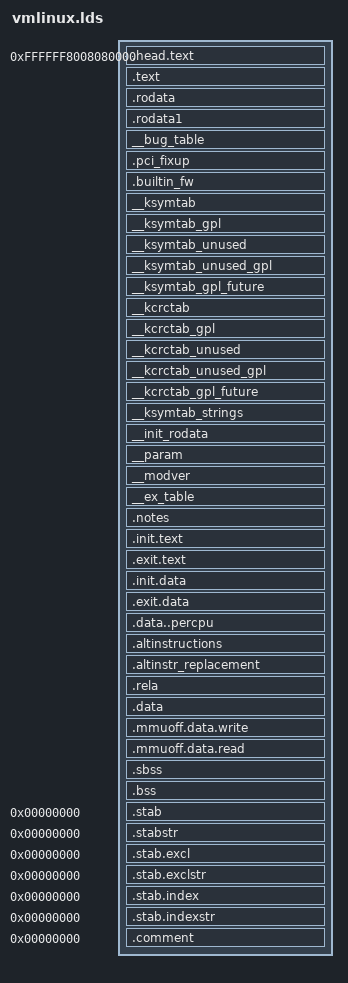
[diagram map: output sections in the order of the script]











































OUTPUT_ARCH(aarch64)
ENTRY(_text)

jiffies = jiffies_64;
PECOFF_FILE_ALIGNMENT = 0x200;
SECTIONS
{






 /DISCARD/ : {


  *(.exitcall.exit)
  *(.discard)
  *(.discard.*)
  *(.interp .dynamic)
  *(.dynsym .dynstr .hash)
 }

 . = ((((0xffffffffffffffff - (1 << (39)) + 1) + (0)) + (0x08000000))) + 0x00080000;

 .head.text : {
  _text = .;
  *(.head.text)
 }
 .text : {
  _stext = .;
   __exception_text_start = .;
   *(.exception.text)
   __exception_text_end = .;
   . = ALIGN(8); __irqentry_text_start = .; *(.irqentry.text) __irqentry_text_end = .;
   . = ALIGN(8); __entry_text_start = .; *(.entry.text) __entry_text_end = .;
   . = ALIGN(8); __softirqentry_text_start = .; *(.softirqentry.text) __softirqentry_text_end = .;
   . = ALIGN(8); *(.text.hot .text .text.fixup .text.unlikely) *(.ref.text)
   . = ALIGN(8); __sched_text_start = .; *(.sched.text) __sched_text_end = .;
   . = ALIGN(8); __cpuidle_text_start = .; *(.cpuidle.text) __cpuidle_text_end = .;
   . = ALIGN(8); __lock_text_start = .; *(.spinlock.text) __lock_text_end = .;
   . = ALIGN(8); __kprobes_text_start = .; *(.kprobes.text) __kprobes_text_end = .;
   . = ALIGN(0x00001000); __hyp_idmap_text_start = .; *(.hyp.idmap.text) __hyp_idmap_text_end = .; __hyp_text_start = .; *(.hyp.text) __hyp_text_end = .;
   . = ALIGN(0x00001000); __idmap_text_start = .; *(.idmap.text) __idmap_text_end = .;


   *(.fixup)
   *(.gnu.warning)
  . = ALIGN(16);
  *(.got)
 }

 . = ALIGN(0x00200000);
 _etext = .;

 . = ALIGN(((1 << 12))); .rodata : AT(ADDR(.rodata) - 0) { __start_rodata = .; *(.rodata) *(.rodata.*) *(.data..ro_after_init) *(__vermagic) . = ALIGN(8); __start___tracepoints_ptrs = .; *(__tracepoints_ptrs) __stop___tracepoints_ptrs = .; *(__tracepoints_strings) } .rodata1 : AT(ADDR(.rodata1) - 0) { *(.rodata1) } . = ALIGN(8); __bug_table : AT(ADDR(__bug_table) - 0) { __start___bug_table = .; *(__bug_table) __stop___bug_table = .; } .pci_fixup : AT(ADDR(.pci_fixup) - 0) { __start_pci_fixups_early = .; *(.pci_fixup_early) __end_pci_fixups_early = .; __start_pci_fixups_header = .; *(.pci_fixup_header) __end_pci_fixups_header = .; __start_pci_fixups_final = .; *(.pci_fixup_final) __end_pci_fixups_final = .; __start_pci_fixups_enable = .; *(.pci_fixup_enable) __end_pci_fixups_enable = .; __start_pci_fixups_resume = .; *(.pci_fixup_resume) __end_pci_fixups_resume = .; __start_pci_fixups_resume_early = .; *(.pci_fixup_resume_early) __end_pci_fixups_resume_early = .; __start_pci_fixups_suspend = .; *(.pci_fixup_suspend) __end_pci_fixups_suspend = .; __start_pci_fixups_suspend_late = .; *(.pci_fixup_suspend_late) __end_pci_fixups_suspend_late = .; } .builtin_fw : AT(ADDR(.builtin_fw) - 0) { __start_builtin_fw = .; *(.builtin_fw) __end_builtin_fw = .; } __ksymtab : AT(ADDR(__ksymtab) - 0) { __start___ksymtab = .; *(SORT(___ksymtab+*)) __stop___ksymtab = .; } __ksymtab_gpl : AT(ADDR(__ksymtab_gpl) - 0) { __start___ksymtab_gpl = .; *(SORT(___ksymtab_gpl+*)) __stop___ksymtab_gpl = .; } __ksymtab_unused : AT(ADDR(__ksymtab_unused) - 0) { __start___ksymtab_unused = .; *(SORT(___ksymtab_unused+*)) __stop___ksymtab_unused = .; } __ksymtab_unused_gpl : AT(ADDR(__ksymtab_unused_gpl) - 0) { __start___ksymtab_unused_gpl = .; *(SORT(___ksymtab_unused_gpl+*)) __stop___ksymtab_unused_gpl = .; } __ksymtab_gpl_future : AT(ADDR(__ksymtab_gpl_future) - 0) { __start___ksymtab_gpl_future = .; *(SORT(___ksymtab_gpl_future+*)) __stop___ksymtab_gpl_future = .; } __kcrctab : AT(ADDR(__kcrctab) - 0) { __start___kcrctab = .; *(SORT(___kcrctab+*)) __stop___kcrctab = .; } __kcrctab_gpl : AT(ADDR(__kcrctab_gpl) - 0) { __start___kcrctab_gpl = .; *(SORT(___kcrctab_gpl+*)) __stop___kcrctab_gpl = .; } __kcrctab_unused : AT(ADDR(__kcrctab_unused) - 0) { __start___kcrctab_unused = .; *(SORT(___kcrctab_unused+*)) __stop___kcrctab_unused = .; } __kcrctab_unused_gpl : AT(ADDR(__kcrctab_unused_gpl) - 0) { __start___kcrctab_unused_gpl = .; *(SORT(___kcrctab_unused_gpl+*)) __stop___kcrctab_unused_gpl = .; } __kcrctab_gpl_future : AT(ADDR(__kcrctab_gpl_future) - 0) { __start___kcrctab_gpl_future = .; *(SORT(___kcrctab_gpl_future+*)) __stop___kcrctab_gpl_future = .; } __ksymtab_strings : AT(ADDR(__ksymtab_strings) - 0) { *(__ksymtab_strings) } __init_rodata : AT(ADDR(__init_rodata) - 0) { *(.ref.rodata) } __param : AT(ADDR(__param) - 0) { __start___param = .; *(__param) __stop___param = .; } __modver : AT(ADDR(__modver) - 0) { __start___modver = .; *(__modver) __stop___modver = .; . = ALIGN(((1 << 12))); __end_rodata = .; } . = ALIGN(((1 << 12)));
 . = ALIGN(8); __ex_table : AT(ADDR(__ex_table) - 0) { __start___ex_table = .; *(__ex_table) __stop___ex_table = .; }
 .notes : AT(ADDR(.notes) - 0) { __start_notes = .; *(.note.*) __stop_notes = .; }

 . = ALIGN(0x00200000);
 __init_begin = .;

 . = ALIGN(8); .init.text : AT(ADDR(.init.text) - 0) { _sinittext = .; *(.init.text) *(.text.startup) *(.meminit.text) _einittext = .; }
 .exit.text : {
  *(.exit.text) *(.text.exit) *(.memexit.text)
 }

 .init.data : {
  *(.init.data) *(.meminit.data) *(.init.rodata) *(.meminit.rodata) . = ALIGN(8); __reservedmem_of_table = .; *(__reservedmem_of_table) *(__reservedmem_of_table_end) . = ALIGN(8); __clksrc_of_table = .; *(__clksrc_of_table) *(__clksrc_of_table_end) . = ALIGN(8); __iommu_of_table = .; *(__iommu_of_table) *(__iommu_of_table_end) . = ALIGN(8); __cpu_method_of_table = .; *(__cpu_method_of_table) *(__cpu_method_of_table_end) . = ALIGN(8); __cpuidle_method_of_table = .; *(__cpuidle_method_of_table) *(__cpuidle_method_of_table_end) . = ALIGN(32); __dtb_start = .; *(.dtb.init.rodata) __dtb_end = .; . = ALIGN(8); __irqchip_of_table = .; *(__irqchip_of_table) *(__irqchip_of_table_end)
  . = ALIGN(16); __setup_start = .; *(.init.setup) __setup_end = .;
  __initcall_start = .; *(.initcallearly.init) __initcall0_start = .; *(.initcall0.init) *(.initcall0s.init) __initcall1_start = .; *(.initcall1.init) *(.initcall1s.init) __initcall2_start = .; *(.initcall2.init) *(.initcall2s.init) __initcall3_start = .; *(.initcall3.init) *(.initcall3s.init) __initcall4_start = .; *(.initcall4.init) *(.initcall4s.init) __initcall5_start = .; *(.initcall5.init) *(.initcall5s.init) __initcallrootfs_start = .; *(.initcallrootfs.init) *(.initcallrootfss.init) __initcall6_start = .; *(.initcall6.init) *(.initcall6s.init) __initcall7_start = .; *(.initcall7.init) *(.initcall7s.init) __initcall_end = .;
  __con_initcall_start = .; *(.con_initcall.init) __con_initcall_end = .;
  __security_initcall_start = .; *(.security_initcall.init) __security_initcall_end = .;
  . = ALIGN(4); __initramfs_start = .; *(.init.ramfs) . = ALIGN(8); *(.init.ramfs.info)
 }
 .exit.data : {
  *(.exit.data) *(.fini_array) *(.dtors) *(.memexit.data) *(.memexit.rodata)
 }

 . = ALIGN((1 << 12)); .data..percpu : AT(ADDR(.data..percpu) - 0) { __per_cpu_load = .; __per_cpu_start = .; __per_cpu_user_mapped_start = .; *(.data..percpu..first) . = ALIGN((1 << 6)); *(.data..percpu..user_mapped) *(.data..percpu..user_mapped..shared_aligned) . = ALIGN((1 << 12)); *(.data..percpu..user_mapped..page_aligned) __per_cpu_user_mapped_end = .; . = ALIGN((1 << 12)); *(.data..percpu..page_aligned) . = ALIGN((1 << 6)); *(.data..percpu..read_mostly) . = ALIGN((1 << 6)); *(.data..percpu) *(.data..percpu..shared_aligned) __per_cpu_end = .; }

 . = ALIGN(4);
 .altinstructions : {
  __alt_instructions = .;
  *(.altinstructions)
  __alt_instructions_end = .;
 }
 .altinstr_replacement : {
  *(.altinstr_replacement)
 }
 .rela : ALIGN(8) {
  *(.rela .rela*)
 }

 __rela_offset = ABSOLUTE(ADDR(.rela) - ((((0xffffffffffffffff - (1 << (39)) + 1) + (0)) + (0x08000000))));
 __rela_size = SIZEOF(.rela);

 . = ALIGN(0x00200000);
 __init_end = .;

 _data = .;
 _sdata = .;
 . = ALIGN((1 << 12)); .data : AT(ADDR(.data) - 0) { . = ALIGN(16384); *(.data..init_task) . = ALIGN((1 << 12)); __nosave_begin = .; *(.data..nosave) . = ALIGN((1 << 12)); __nosave_end = .; . = ALIGN((1 << 12)); *(.data..page_aligned) . = ALIGN((1 << 6)); *(.data..cacheline_aligned) . = ALIGN((1 << 6)); *(.data..read_mostly) . = ALIGN((1 << 6)); *(.data) *(.ref.data) *(.data..shared_aligned) *(.data.unlikely) . = ALIGN(32); *(__tracepoints) . = ALIGN(8); __start___jump_table = .; *(__jump_table) __stop___jump_table = .; . = ALIGN(8); __start___verbose = .; *(__verbose) __stop___verbose = .; CONSTRUCTORS }
 .mmuoff.data.write : ALIGN(0x00000800) {
  __mmuoff_data_start = .;
  *(.mmuoff.data.write)
 }
 . = ALIGN(0x00000800);
 .mmuoff.data.read : {
  *(.mmuoff.data.read)
  __mmuoff_data_end = .;
 }


 _edata = .;

 . = ALIGN(0); __bss_start = .; . = ALIGN(0); .sbss : AT(ADDR(.sbss) - 0) { *(.sbss) *(.scommon) } . = ALIGN(0); .bss : AT(ADDR(.bss) - 0) { *(.bss..page_aligned) *(.dynbss) *(.bss) *(COMMON) } . = ALIGN(0); __bss_stop = .;

 . = ALIGN((1 << 12));
 idmap_pg_dir = .;
 . += ((((((48)) - 4) / (12 - 3)) - 1) * (1 << 12));
 swapper_pg_dir = .;
 . += ((3 - 1) * (1 << 12));
 _end = .;

 .stab 0 : { *(.stab) } .stabstr 0 : { *(.stabstr) } .stab.excl 0 : { *(.stab.excl) } .stab.exclstr 0 : { *(.stab.exclstr) } .stab.index 0 : { *(.stab.index) } .stab.indexstr 0 : { *(.stab.indexstr) } .comment 0 : { *(.comment) }

 _kernel_size_le_lo32 = (((_end - _text) & 0xffffffff) & 0xffffffff); _kernel_size_le_hi32 = (((_end - _text) >> 32) & 0xffffffff); _kernel_offset_le_lo32 = (((0x00080000) & 0xffffffff) & 0xffffffff); _kernel_offset_le_hi32 = (((0x00080000) >> 32) & 0xffffffff); _kernel_flags_le_lo32 = (((((0 << 0) | (((12 - 10) / 2) << 1) | (1 << 3))) & 0xffffffff) & 0xffffffff); _kernel_flags_le_hi32 = (((((0 << 0) | (((12 - 10) / 2) << 1) | (1 << 3))) >> 32) & 0xffffffff);
}





ASSERT(__hyp_idmap_text_end - (__hyp_idmap_text_start & ~(0x00001000 - 1)) <= 0x00001000,
 "HYP init code too big or misaligned")
ASSERT(__idmap_text_end - (__idmap_text_start & ~(0x00001000 - 1)) <= 0x00001000,
 "ID map text too big or misaligned")
ASSERT(_text == (((((0xffffffffffffffff - (1 << (39)) + 1) + (0)) + (0x08000000))) + 0x00080000), "HEAD is misaligned")
